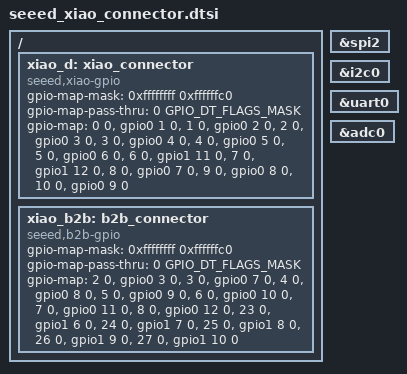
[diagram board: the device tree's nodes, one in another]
/*
 * Copyright (c) 2023 Seeed Studio inc.
 *
 * SPDX-License-Identifier: Apache-2.0
 */

/ {
	xiao_d: xiao_connector {
		compatible = "seeed,xiao-gpio";
		#gpio-cells = <2>;
		gpio-map-mask = <0xffffffff 0xffffffc0>;
		gpio-map-pass-thru = <0 GPIO_DT_FLAGS_MASK>;
		gpio-map = <0 0 &gpio0 1 0>,	/* D0 */
				   <1 0 &gpio0 2 0>,	/* D1 */
				   <2 0 &gpio0 3 0>,	/* D2 */
				   <3 0 &gpio0 4 0>,	/* D3 */
				   <4 0 &gpio0 5 0>,	/* D4 */
				   <5 0 &gpio0 6 0>,	/* D5 */
				   <6 0 &gpio1 11 0>,	/* D6/GPIO43/U0TXD */
				   <7 0 &gpio1 12 0>,	/* D7/GPIO44/U0RXD */
				   <8 0 &gpio0 7 0>,	/* D8 */
				   <9 0 &gpio0 8 0>,	/* D9 */
				   <10 0 &gpio0 9 0>;	/* D10 */
	};

	xiao_b2b: b2b_connector {
		compatible = "seeed,b2b-gpio";
		#gpio-cells = <2>;
		gpio-map-mask = <0xffffffff 0xffffffc0>;
		gpio-map-pass-thru = <0 GPIO_DT_FLAGS_MASK>;
		/* Map starts at board-to-board pin 2 */
			/* 1: GND */
		gpio-map = < 2 0 &gpio0 3 0>,	/* D2 */
			< 3 0 &gpio0 7 0>,	/* D8 */
			< 4 0 &gpio0 8 0>,	/* D9 */
			< 5 0 &gpio0 9 0>,	/* D10 */
			< 6 0 &gpio0 10 0>,	/* IO10 */
			< 7 0 &gpio0 11 0>,	/* IO11 */
			< 8 0 &gpio0 12 0>,	/* IO12 */
			/* 15: Vin */
			/* 17: GND */
			/* 18, 19: Vcc */
			/* 20: NC */
			<23 0 &gpio1 6 0>,	/* IO38 */
			<24 0 &gpio1 7 0>,	/* IO39/MTCK */
			<25 0 &gpio1 8 0>,	/* IO40/MTDO */
			<26 0 &gpio1 9 0>,	/* IO41/MTDI */
			<27 0 &gpio1 10 0>;	/* IO42/MTMS */
			/* 28, 29: GND 30: Vin */
	};
};

xiao_spi: &spi2 {};
xiao_i2c: &i2c0 {};
xiao_serial: &uart0 {};
xiao_adc: &adc0 {};
